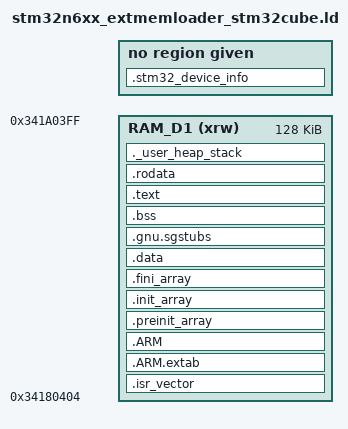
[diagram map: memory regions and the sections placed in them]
/*
******************************************************************************
**
** @file        : LinkerScript.ld
**
** @author      : STM32CubeIDE
**
**  Abstract    : Linker script for STM32N6xx Device
**
**
**                Set heap size, stack size and stack location according
**                to application requirements.
**
**                Set memory bank area and size if external memory is used.
**
**  Target      : STMicroelectronics STM32
**
**  Distribution: The file is distributed as is, without any warranty
**                of any kind.
**
******************************************************************************
** @attention
**
** Copyright (c) 2024 STMicroelectronics.
** All rights reserved.
**
** This software is licensed under terms that can be found in the LICENSE file
** in the root directory of this software component.
** If no LICENSE file comes with this software, it is provided AS-IS.
**
******************************************************************************
*/

/* Entry Point */
ENTRY(Reset_Handler)

/* Generate 2 segment for Loader code and device info */
PHDRS {Loader PT_LOAD FLAGS(5); SgInfo PT_LOAD ; }

/* Highest address of the user mode stack */
_estack = ORIGIN(RAM_D1) + LENGTH(RAM_D1);    /* end of RAM */
/* Generate a link error if heap and stack don't fit into RAM */
_Min_Heap_Size = 0x8;      /* required amount of heap  */
_Min_Stack_Size = 0x400; /* required amount of stack */

/* Memories definition */
MEMORY
{
  RAM_D1 (xrw) : ORIGIN = 0x34180404, LENGTH = 128K-4
}

/* Define output sections */

SECTIONS
{
  /* The startup code goes first into FLASH */
  .isr_vector :
  {
    . = . + 0x1FC;
    . = ALIGN(4);
    KEEP(*(.isr_vector)) /* Startup code */
    . = ALIGN(4);
  } >RAM_D1 :Loader

 .ARM.extab (READONLY) : /* The READONLY keyword is only supported in GCC11 and later, remove it if using GCC10 or earlier. */
 {
  *(.ARM.extab* .gnu.linkonce.armextab.*)
 } >RAM_D1
  .ARM (READONLY) : /* The READONLY keyword is only supported in GCC11 and later, remove it if using GCC10 or earlier. */
  {
    __exidx_start = .;
    *(.ARM.exidx*)
    __exidx_end = .;
  } >RAM_D1 :Loader

  .preinit_array (READONLY) : /* The READONLY keyword is only supported in GCC11 and later, remove it if using GCC10 or earlier. */
  {
    PROVIDE_HIDDEN (__preinit_array_start = .);
    KEEP (*(.preinit_array*))
    PROVIDE_HIDDEN (__preinit_array_end = .);
  } >RAM_D1 :Loader

  .init_array (READONLY) : /* The READONLY keyword is only supported in GCC11 and later, remove it if using GCC10 or earlier. */
  {
    PROVIDE_HIDDEN (__init_array_start = .);
    KEEP (*(SORT(.init_array.*)))
    KEEP (*(.init_array*))
    PROVIDE_HIDDEN (__init_array_end = .);
  } >RAM_D1 :Loader

  .fini_array (READONLY) : /* The READONLY keyword is only supported in GCC11 and later, remove it if using GCC10 or earlier. */
  {
    PROVIDE_HIDDEN (__fini_array_start = .);
    KEEP (*(SORT(.fini_array.*)))
    KEEP (*(.fini_array*))
    PROVIDE_HIDDEN (__fini_array_end = .);
  } >RAM_D1 :Loader

  /* used by the startup to initialize data */
  _sidata = LOADADDR(.data);

  /* Initialized data sections goes into RAM, load LMA copy after code */
  .data :
  {
    . = ALIGN(4);
    _sdata = .;        /* create a global symbol at data start */
    *(.data)           /* .data sections */
    *(.data*)          /* .data* sections */

    . = ALIGN(4);
    _edata = .;        /* define a global symbol at data end */
  } >RAM_D1 :Loader

  .gnu.sgstubs :
  {
    . = ALIGN(4);
    _sNSCVeneer = .;
    *(.gnu.sgstubs*)   /* Secure Gateway stubs */
    _eNSCVeneer = .;
    . = ALIGN(4);
  } >RAM_D1 :Loader

  /* Uninitialized data section */
  . = ALIGN(4);
  .bss :
  {
    /* This is used by the startup in order to initialize the .bss section */
    _sbss = .;         /* define a global symbol at bss start */
    __bss_start__ = _sbss;
    *(.bss)
    *(.bss*)
    *(COMMON)

    . = ALIGN(4);
    _ebss = .;         /* define a global symbol at bss end */
    __bss_end__ = _ebss;
  } >RAM_D1 :Loader

  /* The program code and other data goes into FLASH */
  .text :
  {
    . = ALIGN(4);
    *(.text)           /* .text sections (code) */
    *(.text*)          /* .text* sections (code) */
    *(.glue_7)         /* glue arm to thumb code */
    *(.glue_7t)        /* glue thumb to arm code */
    *(.eh_frame)

    KEEP (*(.init))
    KEEP (*(.fini))

    . = ALIGN(4);
    _etext = .;        /* define a global symbols at end of code */
  } >RAM_D1 :Loader

  .stm32_device_info :
  {
    KEEP(*stm32_device_info.o ( .rodata* ))
  }:SgInfo

  /* Constant data goes into FLASH */
  .rodata :
  {
    . = ALIGN(4);
    *(.rodata)         /* .rodata sections (constants, strings, etc.) */
    *(.rodata*)        /* .rodata* sections (constants, strings, etc.) */
    . = ALIGN(4);
  } >RAM_D1 :Loader

  /* User_heap_stack section, used to check that there is enough RAM left */
  ._user_heap_stack :
  {
    . = ALIGN(8);
    PROVIDE ( end = . );
    PROVIDE ( _end = . );
    . = . + _Min_Heap_Size;
    . = . + _Min_Stack_Size;
    . = ALIGN(8);
  } >RAM_D1 :Loader

  .ARM.attributes 0 : { *(.ARM.attributes) }
}
